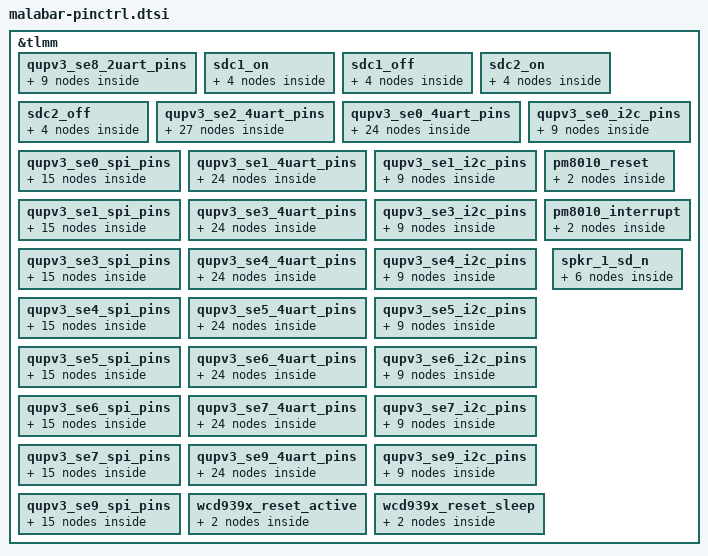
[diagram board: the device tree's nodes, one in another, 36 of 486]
// SPDX-License-Identifier: BSD-3-Clause
/*
 * Copyright (c) Qualcomm Technologies, Inc. and/or its subsidiaries.
 */

&tlmm {
	qupv3_se8_2uart_pins: qupv3_se8_2uart_pins {
		qupv3_se8_2uart_tx_active: qupv3_se8_2uart_tx_active {
			mux {
				pins = "gpio15";
				function = "qup1_se3_l2";
			};

			config {
				pins = "gpio15";
				drive-strength = <2>;
				bias-disable;
			};
		};

		qupv3_se8_2uart_rx_active: qupv3_se8_2uart_rx_active {
			mux {
				pins = "gpio16";
				function = "qup1_se3_l3";
			};

			config {
				pins = "gpio16";
				drive-strength = <2>;
				bias-disable;
			};
		};

		qupv3_se8_2uart_sleep: qupv3_se8_2uart_sleep {
			mux {
				pins = "gpio15", "gpio16";
				function = "gpio";
			};

			config {
				pins = "gpio15", "gpio16";
				drive-strength = <2>;
				bias-pull-down;
			};
		};
	};

	sdc1_on: sdc1_on {
		clk {
			pins = "sdc1_clk";
			bias-disable;
			drive-strength = <16>;
		};

		cmd {
			pins = "sdc1_cmd";
			bias-pull-up;
			drive-strength = <10>;
		};

		data {
			pins = "sdc1_data";
			bias-pull-up;
			drive-strength = <10>;
		};

		rclk {
			pins = "sdc1_rclk";
			bias-pull-down;
		};
	};

	sdc1_off: sdc1_off {
		clk {
			pins = "sdc1_clk";
			bias-disable;
			drive-strength = <2>;
		};

		cmd {
			pins = "sdc1_cmd";
			bias-pull-up;
			drive-strength = <2>;
		};

		data {
			pins = "sdc1_data";
			bias-pull-up;
			drive-strength = <2>;
		};

		rclk {
			pins = "sdc1_rclk";
			bias-pull-down;
		};
	};

	sdc2_on: sdc2_on {
		clk {
			pins = "sdc2_clk";
			bias-disable;
			drive-strength = <16>;
		};

		cmd {
			pins = "sdc2_cmd";
			bias-pull-up;
			drive-strength = <10>;
		};

		data {
			pins = "sdc2_data";
			bias-pull-up;
			drive-strength = <10>;
		};

		sd-cd {
			pins = "gpio79";
			bias-pull-up;
			drive-strength = <2>;
		};
	};

	sdc2_off: sdc2_off {
		clk {
			pins = "sdc2_clk";
			bias-disable;
			drive-strength = <2>;
		};

		cmd {
			pins = "sdc2_cmd";
			bias-pull-up;
			drive-strength = <2>;
		};

		data {
			pins = "sdc2_data";
			bias-pull-up;
			drive-strength = <2>;
		};

		sd-cd {
			pins = "gpio79";
			bias-pull-up;
			drive-strength = <2>;
		};
	};

	qupv3_se2_4uart_pins: qupv3_se2_4uart_pins {
		qupv3_se2_default_cts: qupv3_se2_default_cts {
			mux {
				pins = "gpio17";
				function = "gpio";
			};

			config {
				pins = "gpio17";
				drive-strength = <2>;
				bias-pull-down;
			};
		};

		qupv3_se2_default_rts: qupv3_se2_default_rts {
			mux {
				pins = "gpio18";
				function = "gpio";
			};

			config {
				pins = "gpio18";
				drive-strength = <2>;
				bias-pull-down;
			};
		};

		qupv3_se2_default_tx: qupv3_se2_default_tx {
			mux {
				pins = "gpio19";
				function = "gpio";
			};

			config {
				pins = "gpio19";
				drive-strength = <2>;
				bias-pull-up;
			};
		};

		qupv3_se2_default_rx: qupv3_se2_default_rx {
			mux {
				pins = "gpio20";
				function = "gpio";
			};

			config {
				pins = "gpio20";
				drive-strength = <2>;
				bias-pull-down;
			};
		};

		qupv3_se2_cts: qupv3_se2_cts {
			mux {
				pins = "gpio17";
				function = "qup0_se2_l0";
			};

			config {
				pins = "gpio17";
				drive-strength = <2>;
				bias-disable;
			};
		};

		qupv3_se2_rts: qupv3_se2_rts {
			mux {
				pins = "gpio18";
				function = "qup0_se2_l1";
			};

			config {
				pins = "gpio18";
				drive-strength = <2>;
				bias-pull-down;
			};
		};

		qupv3_se2_tx: qupv3_se2_tx {
			mux {
				pins = "gpio19";
				function = "qup0_se2_l2";
			};

			config {
				pins = "gpio19";
				drive-strength = <2>;
				bias-pull-up;
			};
		};

		qupv3_se2_rx_active: qupv3_se2_rx_active {
			mux {
				pins = "gpio20";
				function = "qup0_se2_l3";
			};

			config {
				pins = "gpio20";
				drive-strength = <2>;
				bias-disable;
			};
		};

		qupv3_se2_rx_wake: qupv3_se2_rx_wake {
			mux {
				pins = "gpio20";
				function = "gpio";
			};

			config {
				pins = "gpio20";
				drive-strength = <2>;
				bias-disable;
			};
		};
	};

	qupv3_se0_4uart_pins: qupv3_se0_4uart_pins {
		qupv3_se0_default_cts: qupv3_se0_default_cts {
			mux {
				pins = "gpio0";
				function = "gpio";
			};

			config {
				pins = "gpio0";
				drive-strength = <2>;
				bias-disable;
			};
		};

		qupv3_se0_default_rts: qupv3_se0_default_rts {
			mux {
				pins = "gpio1";
				function = "gpio";
			};

			config {
				pins = "gpio1";
				drive-strength = <2>;
				bias-pull-down;
			};
		};

		qupv3_se0_default_tx: qupv3_se0_default_tx {
			mux {
				pins = "gpio2";
				function = "gpio";
			};

			config {
				pins = "gpio2";
				drive-strength = <2>;
				bias-pull-up;
			};
		};

		qupv3_se0_default_rx: qupv3_se0_default_rx {
			mux {
				pins = "gpio3";
				function = "gpio";
			};

			config {
				pins = "gpio3";
				drive-strength = <2>;
				bias-pull-down;
			};
		};

		qupv3_se0_cts: qupv3_se0_cts {
			mux {
				pins = "gpio0";
				function = "qup0_se0_l0";
			};

			config {
				pins = "gpio0";
				drive-strength = <2>;
				bias-disable;
			};
		};

		qupv3_se0_rts: qupv3_se0_rts {
			mux {
				pins = "gpio1";
				function = "qup0_se0_l1";
			};

			config {
				pins = "gpio1";
				drive-strength = <2>;
				bias-pull-down;
			};
		};

		qupv3_se0_tx: qupv3_se0_tx {
			mux {
				pins = "gpio2";
				function = "qup0_se0_l2";
			};

			config {
				pins = "gpio2";
				drive-strength = <2>;
				bias-pull-up;
			};
		};

		qupv3_se0_rx_active: qupv3_se0_rx_active {
			mux {
				pins = "gpio3";
				function = "qup0_se0_l3";
			};

			config {
				pins = "gpio3";
				drive-strength = <2>;
				bias-disable;
			};
		};
	};

	qupv3_se0_i2c_pins: qupv3_se0_i2c_pins {
		qupv3_se0_i2c_sda_active: qupv3_se0_i2c_sda_active {
			mux {
				pins = "gpio0";
				function = "qup0_se0_l0";
			};

			config {
				pins = "gpio0";
				drive-strength = <2>;
				bias-pull-up;
			};
		};

		qupv3_se0_i2c_scl_active: qupv3_se0_i2c_scl_active {
			mux {
				pins = "gpio1";
				function = "qup0_se0_l1";
			};

			config {
				pins = "gpio1";
				drive-strength = <2>;
				bias-pull-up;
			};
		};

		qupv3_se0_i2c_sleep: qupv3_se0_i2c_sleep {
			mux {
				pins = "gpio0", "gpio1";
				function = "gpio";
			};

			config {
				pins = "gpio0", "gpio1";
				drive-strength = <2>;
				bias-disable;
			};
		};
	};

	qupv3_se0_spi_pins: qupv3_se0_spi_pins {
		qupv3_se0_spi_miso_active: qupv3_se0_spi_miso_active {
			mux {
				pins = "gpio0";
				function = "qup0_se0_l0";
			};

			config {
				pins = "gpio0";
				drive-strength = <6>;
				bias-disable;
			};
		};

		qupv3_se0_spi_mosi_active: qupv3_se0_spi_mosi_active {
			mux {
				pins = "gpio1";
				function = "qup0_se0_l1";
			};

			config {
				pins = "gpio1";
				drive-strength = <6>;
				bias-disable;
			};
		};

		qupv3_se0_spi_clk_active: qupv3_se0_spi_clk_active {
			mux {
				pins = "gpio2";
				function = "qup0_se0_l2";
			};

			config {
				pins = "gpio2";
				drive-strength = <6>;
				bias-disable;
			};
		};

		qupv3_se0_spi_cs_active: qupv3_se0_spi_cs_active {
			mux {
				pins = "gpio3";
				function = "qup0_se0_l3";
			};

			config {
				pins = "gpio3";
				drive-strength = <6>;
				bias-disable;
			};
		};

		qupv3_se0_spi_sleep: qupv3_se0_spi_sleep {
			mux {
				pins = "gpio0", "gpio1",
					"gpio2", "gpio3";
				function = "gpio";
			};

			config {
				pins = "gpio0", "gpio1",
					"gpio2", "gpio3";
				drive-strength = <2>;
				bias-disable;
			};
		};
	};

	qupv3_se1_4uart_pins: qupv3_se1_4uart_pins {
		qupv3_se1_default_cts: qupv3_se1_default_cts {
			mux {
				pins = "gpio4";
				function = "gpio";
			};

			config {
				pins = "gpio4";
				drive-strength = <2>;
				bias-disable;
			};
		};

		qupv3_se1_default_rts: qupv3_se1_default_rts {
			mux {
				pins = "gpio5";
				function = "gpio";
			};

			config {
				pins = "gpio5";
				drive-strength = <2>;
				bias-pull-down;
			};
		};

		qupv3_se1_default_tx: qupv3_se1_default_tx {
			mux {
				pins = "gpio23";
				function = "gpio";
			};

			config {
				pins = "gpio23";
				drive-strength = <2>;
				bias-pull-up;
			};
		};

		qupv3_se1_default_rx: qupv3_se1_default_rx {
			mux {
				pins = "gpio77";
				function = "gpio";
			};

			config {
				pins = "gpio77";
				drive-strength = <2>;
				bias-pull-down;
			};
		};

		qupv3_se1_cts: qupv3_se1_cts {
			mux {
				pins = "gpio4";
				function = "qup0_se1_l0";
			};

			config {
				pins = "gpio4";
				drive-strength = <2>;
				bias-disable;
			};
		};

		qupv3_se1_rts: qupv3_se1_rts {
			mux {
				pins = "gpio5";
				function = "qup0_se1_l1";
			};

			config {
				pins = "gpio5";
				drive-strength = <2>;
				bias-pull-down;
			};
		};

		qupv3_se1_tx: qupv3_se1_tx {
			mux {
				pins = "gpio23";
				function = "qup0_se1_l2";
			};

			config {
				pins = "gpio23";
				drive-strength = <2>;
				bias-pull-up;
			};
		};

		qupv3_se1_rx_active: qupv3_se1_rx_active {
			mux {
				pins = "gpio77";
				function = "qup0_se1_l3";
			};

			config {
				pins = "gpio77";
				drive-strength = <2>;
				bias-disable;
			};
		};
	};

	qupv3_se1_i2c_pins: qupv3_se1_i2c_pins {
		qupv3_se1_i2c_sda_active: qupv3_se1_i2c_sda_active {
			mux {
				pins = "gpio4";
				function = "qup0_se1_l0";
			};

			config {
				pins = "gpio4";
				drive-strength = <2>;
				bias-pull-up;
			};
		};

		qupv3_se1_i2c_scl_active: qupv3_se1_i2c_scl_active {
			mux {
				pins = "gpio5";
				function = "qup0_se1_l1";
			};

			config {
				pins = "gpio5";
				drive-strength = <2>;
				bias-pull-up;
			};
		};

		qupv3_se1_i2c_sleep: qupv3_se1_i2c_sleep {
			mux {
				pins = "gpio4", "gpio5";
				function = "gpio";
			};

			config {
				pins = "gpio4", "gpio5";
				drive-strength = <2>;
				bias-disable;
			};
		};
	};

	qupv3_se1_spi_pins: qupv3_se1_spi_pins {
		qupv3_se1_spi_miso_active: qupv3_se1_spi_miso_active {
			mux {
				pins = "gpio4";
				function = "qup0_se1_l0";
			};

			config {
				pins = "gpio4";
				drive-strength = <6>;
				bias-disable;
			};
		};

		qupv3_se1_spi_mosi_active: qupv3_se1_spi_mosi_active {
			mux {
				pins = "gpio5";
				function = "qup0_se1_l1";
			};

			config {
				pins = "gpio5";
				drive-strength = <6>;
				bias-disable;
			};
		};

		qupv3_se1_spi_clk_active: qupv3_se1_spi_clk_active {
			mux {
				pins = "gpio23";
				function = "qup0_se1_l2";
			};

			config {
				pins = "gpio23";
				drive-strength = <6>;
				bias-disable;
			};
		};

		qupv3_se1_spi_cs_active: qupv3_se1_spi_cs_active {
			mux {
				pins = "gpio77";
				function = "qup0_se1_l3";
			};

			config {
				pins = "gpio77";
				drive-strength = <6>;
				bias-disable;
			};
		};

		qupv3_se1_spi_sleep: qupv3_se1_spi_sleep {
			mux {
				pins = "gpio4", "gpio5",
					"gpio23", "gpio77";
				function = "gpio";
			};

			config {
				pins = "gpio4", "gpio5",
					"gpio23", "gpio77";
				drive-strength = <2>;
				bias-disable;
			};
		};
	};

	qupv3_se3_4uart_pins: qupv3_se3_4uart_pins {
		qupv3_se3_default_cts: qupv3_se3_default_cts {
			mux {
				pins = "gpio8";
				function = "gpio";
			};

			config {
				pins = "gpio8";
				drive-strength = <2>;
				bias-disable;
			};
		};

		qupv3_se3_default_rts: qupv3_se3_default_rts {
			mux {
				pins = "gpio9";
				function = "gpio";
			};

			config {
				pins = "gpio9";
				drive-strength = <2>;
				bias-pull-down;
			};
		};

		qupv3_se3_default_tx: qupv3_se3_default_tx {
			mux {
				pins = "gpio10";
				function = "gpio";
			};

			config {
				pins = "gpio10";
				drive-strength = <2>;
				bias-pull-up;
			};
		};

		qupv3_se3_default_rx: qupv3_se3_default_rx {
			mux {
				pins = "gpio11";
				function = "gpio";
			};

			config {
				pins = "gpio11";
				drive-strength = <2>;
				bias-pull-down;
			};
		};

		qupv3_se3_cts: qupv3_se3_cts {
			mux {
				pins = "gpio8";
				function = "qup0_se3_l0";
			};

			config {
				pins = "gpio8";
				drive-strength = <2>;
				bias-disable;
			};
		};

		qupv3_se3_rts: qupv3_se3_rts {
			mux {
				pins = "gpio9";
				function = "qup0_se3_l1";
			};

			config {
				pins = "gpio9";
				drive-strength = <2>;
				bias-pull-down;
			};
		};

		qupv3_se3_tx: qupv3_se3_tx {
			mux {
				pins = "gpio10";
				function = "qup0_se3_l2";
			};

			config {
				pins = "gpio10";
				drive-strength = <2>;
				bias-pull-up;
			};
		};

		qupv3_se3_rx_active: qupv3_se3_rx_active {
			mux {
				pins = "gpio11";
				function = "qup0_se3_l3";
			};

			config {
				pins = "gpio11";
				drive-strength = <2>;
				bias-disable;
			};
		};
	};

	qupv3_se3_i2c_pins: qupv3_se3_i2c_pins {
		qupv3_se3_i2c_sda_active: qupv3_se3_i2c_sda_active {
			mux {
				pins = "gpio8";
				function = "qup0_se3_l0";
			};

			config {
				pins = "gpio8";
				drive-strength = <2>;
				bias-pull-up;
			};
		};

		qupv3_se3_i2c_scl_active: qupv3_se3_i2c_scl_active {
			mux {
				pins = "gpio9";
				function = "qup0_se3_l1";
			};

			config {
				pins = "gpio9";
				drive-strength = <2>;
				bias-pull-up;
			};
		};

		qupv3_se3_i2c_sleep: qupv3_se3_i2c_sleep {
			mux {
				pins = "gpio8", "gpio9";
				function = "gpio";
			};

			config {
				pins = "gpio8", "gpio9";
				drive-strength = <2>;
				bias-disable;
			};
		};
	};

	qupv3_se3_spi_pins: qupv3_se3_spi_pins {
		qupv3_se3_spi_miso_active: qupv3_se3_spi_miso_active {
			mux {
				pins = "gpio8";
				function = "qup0_se3_l0";
			};

			config {
				pins = "gpio8";
				drive-strength = <6>;
				bias-disable;
			};
		};

		qupv3_se3_spi_mosi_active: qupv3_se3_spi_mosi_active {
			mux {
				pins = "gpio9";
				function = "qup0_se3_l1";
			};

			config {
				pins = "gpio9";
				drive-strength = <6>;
				bias-disable;
			};
		};

		qupv3_se3_spi_clk_active: qupv3_se3_spi_clk_active {
			mux {
				pins = "gpio10";
				function = "qup0_se3_l2";
			};

			config {
				pins = "gpio10";
				drive-strength = <6>;
				bias-disable;
			};
		};

		qupv3_se3_spi_cs_active: qupv3_se3_spi_cs_active {
			mux {
				pins = "gpio11";
				function = "qup0_se3_l3";
			};

			config {
				pins = "gpio11";
				drive-strength = <6>;
				bias-disable;
			};
		};

		qupv3_se3_spi_sleep: qupv3_se3_spi_sleep {
			mux {
				pins = "gpio8", "gpio9",
					"gpio10", "gpio11";
				function = "gpio";
			};

			config {
				pins = "gpio8", "gpio9",
					"gpio10", "gpio11";
				drive-strength = <2>;
				bias-disable;
			};
		};
	};

	qupv3_se4_4uart_pins: qupv3_se4_4uart_pins {
		qupv3_se4_default_cts: qupv3_se4_default_cts {
			mux {
				pins = "gpio6";
				function = "gpio";
			};

			config {
				pins = "gpio6";
				drive-strength = <2>;
				bias-disable;
			};
		};

		qupv3_se4_default_rts: qupv3_se4_default_rts {
			mux {
				pins = "gpio7";
				function = "gpio";
			};

			config {
				pins = "gpio7";
				drive-strength = <2>;
				bias-pull-down;
			};
		};

		qupv3_se4_default_tx: qupv3_se4_default_tx {
			mux {
				pins = "gpio12";
				function = "gpio";
			};

			config {
				pins = "gpio12";
				drive-strength = <2>;
				bias-pull-up;
			};
		};

		qupv3_se4_default_rx: qupv3_se4_default_rx {
			mux {
				pins = "gpio13";
				function = "gpio";
			};

			config {
				pins = "gpio13";
				drive-strength = <2>;
				bias-pull-down;
			};
		};

		qupv3_se4_cts: qupv3_se4_cts {
			mux {
				pins = "gpio6";
				function = "qup0_se4_l0";
			};

			config {
				pins = "gpio6";
				drive-strength = <2>;
				bias-disable;
			};
		};

		qupv3_se4_rts: qupv3_se4_rts {
			mux {
				pins = "gpio7";
				function = "qup0_se4_l1";
			};

			config {
				pins = "gpio7";
				drive-strength = <2>;
				bias-pull-down;
			};
		};

		qupv3_se4_tx: qupv3_se4_tx {
			mux {
				pins = "gpio12";
				function = "qup0_se4_l2";
			};

			config {
				pins = "gpio12";
				drive-strength = <2>;
				bias-pull-up;
			};
		};

		qupv3_se4_rx_active: qupv3_se4_rx_active {
			mux {
				pins = "gpio13";
				function = "qup0_se4_l3";
			};

			config {
				pins = "gpio13";
				drive-strength = <2>;
				bias-disable;
			};
		};
	};

	qupv3_se4_i2c_pins: qupv3_se4_i2c_pins {
		qupv3_se4_i2c_sda_active: qupv3_se4_i2c_sda_active {
			mux {
				pins = "gpio6";
				function = "qup0_se4_l0";
			};

			config {
				pins = "gpio6";
				drive-strength = <2>;
				bias-pull-up;
			};
		};

		qupv3_se4_i2c_scl_active: qupv3_se4_i2c_scl_active {
			mux {
				pins = "gpio7";
				function = "qup0_se4_l1";
			};

			config {
				pins = "gpio7";
				drive-strength = <2>;
				bias-pull-up;
			};
		};

		qupv3_se4_i2c_sleep: qupv3_se4_i2c_sleep {
			mux {
				pins = "gpio6", "gpio7";
				function = "gpio";
			};

			config {
				pins = "gpio6", "gpio7";
				drive-strength = <2>;
				bias-disable;
			};
		};
	};

	qupv3_se4_spi_pins: qupv3_se4_spi_pins {
		qupv3_se4_spi_miso_active: qupv3_se4_spi_miso_active {
			mux {
				pins = "gpio6";
				function = "qup0_se4_l0";
			};

			config {
				pins = "gpio6";
				drive-strength = <6>;
				bias-disable;
			};
		};

		qupv3_se4_spi_mosi_active: qupv3_se4_spi_mosi_active {
			mux {
				pins = "gpio7";
				function = "qup0_se4_l1";
			};

			config {
				pins = "gpio7";
				drive-strength = <6>;
				bias-disable;
			};
		};

		qupv3_se4_spi_clk_active: qupv3_se4_spi_clk_active {
			mux {
				pins = "gpio12";
				function = "qup0_se4_l2";
			};

			config {
				pins = "gpio12";
				drive-strength = <6>;
				bias-disable;
			};
		};

		qupv3_se4_spi_cs_active: qupv3_se4_spi_cs_active {
			mux {
				pins = "gpio13";
				function = "qup0_se4_l3";
			};

			config {
				pins = "gpio13";
				drive-strength = <6>;
				bias-disable;
			};
		};

		qupv3_se4_spi_sleep: qupv3_se4_spi_sleep {
			mux {
				pins = "gpio6", "gpio7",
					"gpio12", "gpio13";
				function = "gpio";
			};

			config {
				pins = "gpio6", "gpio7",
					"gpio12", "gpio13";
				drive-strength = <2>;
				bias-disable;
			};
		};
	};

	qupv3_se5_4uart_pins: qupv3_se5_4uart_pins {
		qupv3_se5_default_cts: qupv3_se5_default_cts {
			mux {
				pins = "gpio36";
				function = "gpio";
			};

			config {
				pins = "gpio36";
				drive-strength = <2>;
				bias-disable;
			};
		};

		qupv3_se5_default_rts: qupv3_se5_default_rts {
			mux {
				pins = "gpio37";
				function = "gpio";
			};

			config {
				pins = "gpio37";
				drive-strength = <2>;
				bias-pull-down;
			};
		};

		qupv3_se5_default_tx: qupv3_se5_default_tx {
			mux {
				pins = "gpio38";
				function = "gpio";
			};

			config {
				pins = "gpio38";
				drive-strength = <2>;
				bias-pull-up;
			};
		};

		qupv3_se5_default_rx: qupv3_se5_default_rx {
			mux {
				pins = "gpio39";
				function = "gpio";
			};

			config {
				pins = "gpio39";
				drive-strength = <2>;
				bias-pull-down;
			};
		};

		qupv3_se5_cts: qupv3_se5_cts {
			mux {
				pins = "gpio36";
				function = "qup1_se0_l0";
			};

			config {
				pins = "gpio36";
				drive-strength = <2>;
				bias-disable;
			};
		};

		qupv3_se5_rts: qupv3_se5_rts {
			mux {
				pins = "gpio37";
				function = "qup1_se0_l1";
			};

			config {
				pins = "gpio37";
				drive-strength = <2>;
				bias-pull-down;
			};
		};

		qupv3_se5_tx: qupv3_se5_tx {
			mux {
				pins = "gpio38";
				function = "qup1_se0_l2";
			};

			config {
				pins = "gpio38";
				drive-strength = <2>;
				bias-pull-up;
			};
		};

		qupv3_se5_rx_active: qupv3_se5_rx_active {
			mux {
				pins = "gpio39";
				function = "qup1_se0_l3";
			};

			config {
				pins = "gpio39";
				drive-strength = <2>;
				bias-disable;
			};
		};
	};

	qupv3_se5_i2c_pins: qupv3_se5_i2c_pins {
		qupv3_se5_i2c_sda_active: qupv3_se5_i2c_sda_active {
			mux {
				pins = "gpio36";
				function = "qup1_se0_l0";
			};

			config {
				pins = "gpio36";
				drive-strength = <2>;
				bias-pull-up;
			};
		};

		qupv3_se5_i2c_scl_active: qupv3_se5_i2c_scl_active {
			mux {
				pins = "gpio37";
				function = "qup1_se0_l1";
			};

			config {
				pins = "gpio37";
				drive-strength = <2>;
				bias-pull-up;
			};
		};

		qupv3_se5_i2c_sleep: qupv3_se5_i2c_sleep {
			mux {
				pins = "gpio36", "gpio37";
				function = "gpio";
			};

			config {
				pins = "gpio36", "gpio37";
				drive-strength = <2>;
				bias-disable;
			};
		};
	};

	qupv3_se5_spi_pins: qupv3_se5_spi_pins {
		qupv3_se5_spi_miso_active: qupv3_se5_spi_miso_active {
			mux {
				pins = "gpio36";
				function = "qup1_se0_l0";
			};

			config {
				pins = "gpio36";
				drive-strength = <6>;
				bias-disable;
			};
		};

		qupv3_se5_spi_mosi_active: qupv3_se5_spi_mosi_active {
			mux {
				pins = "gpio37";
				function = "qup1_se0_l1";
			};

			config {
				pins = "gpio37";
				drive-strength = <6>;
				bias-disable;
			};
		};

		qupv3_se5_spi_clk_active: qupv3_se5_spi_clk_active {
			mux {
				pins = "gpio38";
				function = "qup1_se0_l2";
			};

			config {
				pins = "gpio38";
				drive-strength = <6>;
				bias-disable;
			};
		};

		qupv3_se5_spi_cs_active: qupv3_se5_spi_cs_active {
			mux {
				pins = "gpio39";
				function = "qup1_se0_l3";
			};

			config {
				pins = "gpio39";
				drive-strength = <6>;
				bias-disable;
			};
		};

		qupv3_se5_spi_sleep: qupv3_se5_spi_sleep {
			mux {
				pins = "gpio36", "gpio37",
					"gpio38", "gpio39";
				function = "gpio";
			};

			config {
				pins = "gpio36", "gpio37",
					"gpio38", "gpio39";
				drive-strength = <2>;
				bias-disable;
			};
		};
	};

	qupv3_se6_4uart_pins: qupv3_se6_4uart_pins {
		qupv3_se6_default_cts: qupv3_se6_default_cts {
			mux {
				pins = "gpio78";
				function = "gpio";
			};

			config {
				pins = "gpio78";
				drive-strength = <2>;
				bias-disable;
			};
		};

		qupv3_se6_default_rts: qupv3_se6_default_rts {
			mux {
				pins = "gpio79";
				function = "gpio";
			};

			config {
				pins = "gpio79";
				drive-strength = <2>;
				bias-pull-down;
			};
		};

		qupv3_se6_default_tx: qupv3_se6_default_tx {
			mux {
				pins = "gpio69";
				function = "gpio";
			};

			config {
				pins = "gpio69";
				drive-strength = <2>;
				bias-pull-up;
			};
		};

		qupv3_se6_default_rx: qupv3_se6_default_rx {
			mux {
				pins = "gpio70";
				function = "gpio";
			};

			config {
				pins = "gpio70";
				drive-strength = <2>;
				bias-pull-down;
			};
		};

		qupv3_se6_cts: qupv3_se6_cts {
			mux {
				pins = "gpio78";
				function = "qup1_se1_l0";
			};

			config {
				pins = "gpio78";
				drive-strength = <2>;
				bias-disable;
			};
		};

		qupv3_se6_rts: qupv3_se6_rts {
			mux {
				pins = "gpio79";
				function = "qup1_se1_l1";
			};

			config {
				pins = "gpio79";
				drive-strength = <2>;
				bias-pull-down;
			};
		};

		qupv3_se6_tx: qupv3_se6_tx {
			mux {
				pins = "gpio69";
				function = "qup1_se1_l2";
			};

			config {
				pins = "gpio69";
				drive-strength = <2>;
				bias-pull-up;
			};
		};

		qupv3_se6_rx_active: qupv3_se6_rx_active {
			mux {
				pins = "gpio70";
				function = "qup1_se1_l3";
			};

			config {
				pins = "gpio70";
				drive-strength = <2>;
				bias-disable;
			};
		};
	};

	qupv3_se6_i2c_pins: qupv3_se6_i2c_pins {
		qupv3_se6_i2c_sda_active: qupv3_se6_i2c_sda_active {
			mux {
				pins = "gpio78";
				function = "qup1_se1_l0";
			};

			config {
				pins = "gpio78";
				drive-strength = <2>;
				bias-pull-up;
			};
		};

		qupv3_se6_i2c_scl_active: qupv3_se6_i2c_scl_active {
			mux {
				pins = "gpio79";
				function = "qup1_se1_l1";
			};

			config {
				pins = "gpio79";
				drive-strength = <2>;
				bias-pull-up;
			};
		};

		qupv3_se6_i2c_sleep: qupv3_se6_i2c_sleep {
			mux {
				pins = "gpio78", "gpio79";
				function = "gpio";
			};

			config {
				pins = "gpio78", "gpio79";
				drive-strength = <2>;
				bias-disable;
			};
		};
	};

	qupv3_se6_spi_pins: qupv3_se6_spi_pins {
		qupv3_se6_spi_miso_active: qupv3_se6_spi_miso_active {
			mux {
				pins = "gpio78";
				function = "qup1_se1_l0";
			};

			config {
				pins = "gpio78";
				drive-strength = <6>;
				bias-disable;
			};
		};

		qupv3_se6_spi_mosi_active: qupv3_se6_spi_mosi_active {
			mux {
				pins = "gpio79";
				function = "qup1_se1_l1";
			};

			config {
				pins = "gpio79";
				drive-strength = <6>;
				bias-disable;
			};
		};

		qupv3_se6_spi_clk_active: qupv3_se6_spi_clk_active {
			mux {
				pins = "gpio69";
				function = "qup1_se1_l2";
			};

			config {
				pins = "gpio69";
				drive-strength = <6>;
				bias-disable;
			};
		};

		qupv3_se6_spi_cs_active: qupv3_se6_spi_cs_active {
			mux {
				pins = "gpio70";
				function = "qup1_se1_l3";
			};

			config {
				pins = "gpio70";
				drive-strength = <6>;
				bias-disable;
			};
		};

		qupv3_se6_spi_sleep: qupv3_se6_spi_sleep {
			mux {
				pins = "gpio78", "gpio79",
					"gpio69", "gpio70";
				function = "gpio";
			};

			config {
				pins = "gpio78", "gpio79",
					"gpio69", "gpio70";
				drive-strength = <2>;
				bias-disable;
			};
		};
	};

	qupv3_se7_4uart_pins: qupv3_se7_4uart_pins {
		qupv3_se7_default_cts: qupv3_se7_default_cts {
			mux {
				pins = "gpio40";
				function = "gpio";
			};

			config {
				pins = "gpio40";
				drive-strength = <2>;
				bias-disable;
			};
		};

		qupv3_se7_default_rts: qupv3_se7_default_rts {
			mux {
				pins = "gpio41";
				function = "gpio";
			};

			config {
				pins = "gpio41";
				drive-strength = <2>;
				bias-pull-down;
			};
		};

		qupv3_se7_default_tx: qupv3_se7_default_tx {
			mux {
				pins = "gpio42";
				function = "gpio";
			};

			config {
				pins = "gpio42";
				drive-strength = <2>;
				bias-pull-up;
			};
		};

		qupv3_se7_default_rx: qupv3_se7_default_rx {
			mux {
				pins = "gpio43";
				function = "gpio";
			};

			config {
				pins = "gpio43";
				drive-strength = <2>;
				bias-pull-down;
			};
		};

		qupv3_se7_cts: qupv3_se7_cts {
			mux {
				pins = "gpio40";
				function = "qup1_se2_l0";
			};

			config {
				pins = "gpio40";
				drive-strength = <2>;
				bias-disable;
			};
		};

		qupv3_se7_rts: qupv3_se7_rts {
			mux {
				pins = "gpio41";
				function = "qup1_se2_l1";
			};

			config {
				pins = "gpio41";
				drive-strength = <2>;
				bias-pull-down;
			};
		};

		qupv3_se7_tx: qupv3_se7_tx {
			mux {
				pins = "gpio42";
				function = "qup1_se2_l2";
			};

			config {
				pins = "gpio42";
				drive-strength = <2>;
				bias-pull-up;
			};
		};

		qupv3_se7_rx_active: qupv3_se7_rx_active {
			mux {
				pins = "gpio43";
				function = "qup1_se2_l3";
			};

			config {
				pins = "gpio43";
				drive-strength = <2>;
				bias-disable;
			};
		};
	};

	qupv3_se7_i2c_pins: qupv3_se7_i2c_pins {
		qupv3_se7_i2c_sda_active: qupv3_se7_i2c_sda_active {
			mux {
				pins = "gpio40";
				function = "qup1_se2_l0";
			};

			config {
				pins = "gpio40";
				drive-strength = <2>;
				bias-pull-up;
			};
		};

		qupv3_se7_i2c_scl_active: qupv3_se7_i2c_scl_active {
			mux {
				pins = "gpio41";
				function = "qup1_se2_l1";
			};

			config {
				pins = "gpio41";
				drive-strength = <2>;
				bias-pull-up;
			};
		};

		qupv3_se7_i2c_sleep: qupv3_se7_i2c_sleep {
			mux {
				pins = "gpio40", "gpio41";
				function = "gpio";
			};

			config {
				pins = "gpio40", "gpio41";
				drive-strength = <2>;
				bias-disable;
			};
		};
	};

	qupv3_se7_spi_pins: qupv3_se7_spi_pins {
		qupv3_se7_spi_miso_active: qupv3_se7_spi_miso_active {
			mux {
				pins = "gpio40";
				function = "qup1_se2_l0";
			};

			config {
				pins = "gpio40";
				drive-strength = <6>;
				bias-disable;
			};
		};

		qupv3_se7_spi_mosi_active: qupv3_se7_spi_mosi_active {
			mux {
				pins = "gpio41";
				function = "qup1_se2_l1";
			};

			config {
				pins = "gpio41";
				drive-strength = <6>;
				bias-disable;
			};
		};

		qupv3_se7_spi_clk_active: qupv3_se7_spi_clk_active {
			mux {
				pins = "gpio42";
				function = "qup1_se2_l2";
			};

			config {
				pins = "gpio42";
				drive-strength = <6>;
				bias-disable;
			};
		};

		qupv3_se7_spi_cs_active: qupv3_se7_spi_cs_active {
			mux {
				pins = "gpio43";
				function = "qup1_se2_l3";
			};

			config {
				pins = "gpio43";
				drive-strength = <6>;
				bias-disable;
			};
		};

		qupv3_se7_spi_sleep: qupv3_se7_spi_sleep {
			mux {
				pins = "gpio40", "gpio41",
					"gpio42", "gpio43";
				function = "gpio";
			};

			config {
				pins = "gpio40", "gpio41",
					"gpio42", "gpio43";
				drive-strength = <2>;
				bias-disable;
			};
		};
	};

	qupv3_se9_4uart_pins: qupv3_se9_4uart_pins {
		qupv3_se9_default_cts: qupv3_se9_default_cts {
			mux {
				pins = "gpio71";
				function = "gpio";
			};

			config {
				pins = "gpio71";
				drive-strength = <2>;
				bias-disable;
			};
		};

		qupv3_se9_default_rts: qupv3_se9_default_rts {
			mux {
				pins = "gpio72";
				function = "gpio";
			};

			config {
				pins = "gpio72";
				drive-strength = <2>;
				bias-pull-down;
			};
		};

		qupv3_se9_default_tx: qupv3_se9_default_tx {
			mux {
				pins = "gpio73";
				function = "gpio";
			};

			config {
				pins = "gpio73";
				drive-strength = <2>;
				bias-pull-up;
			};
		};

		qupv3_se9_default_rx: qupv3_se9_default_rx {
			mux {
				pins = "gpio74";
				function = "gpio";
			};

			config {
				pins = "gpio74";
				drive-strength = <2>;
				bias-pull-down;
			};
		};

		qupv3_se9_cts: qupv3_se9_cts {
			mux {
				pins = "gpio71";
				function = "qup1_se4_l0";
			};

			config {
				pins = "gpio71";
				drive-strength = <2>;
				bias-disable;
			};
		};

		qupv3_se9_rts: qupv3_se9_rts {
			mux {
				pins = "gpio72";
				function = "qup1_se4_l1";
			};

			config {
				pins = "gpio72";
				drive-strength = <2>;
				bias-pull-down;
			};
		};

		qupv3_se9_tx: qupv3_se9_tx {
			mux {
				pins = "gpio73";
				function = "qup1_se4_l2";
			};

			config {
				pins = "gpio73";
				drive-strength = <2>;
				bias-pull-up;
			};
		};

		qupv3_se9_rx_active: qupv3_se9_rx_active {
			mux {
				pins = "gpio74";
				function = "qup1_se4_l3";
			};

			config {
				pins = "gpio74";
				drive-strength = <2>;
				bias-disable;
			};
		};
	};

	qupv3_se9_i2c_pins: qupv3_se9_i2c_pins {
		qupv3_se9_i2c_sda_active: qupv3_se9_i2c_sda_active {
			mux {
				pins = "gpio71";
				function = "qup1_se4_l0";
			};

			config {
				pins = "gpio71";
				drive-strength = <2>;
				bias-pull-up;
			};
		};

		qupv3_se9_i2c_scl_active: qupv3_se9_i2c_scl_active {
			mux {
				pins = "gpio72";
				function = "qup1_se4_l1";
			};

			config {
				pins = "gpio72";
				drive-strength = <2>;
				bias-pull-up;
			};
		};

		qupv3_se9_i2c_sleep: qupv3_se9_i2c_sleep {
			mux {
				pins = "gpio71", "gpio72";
				function = "gpio";
			};

			config {
				pins = "gpio71", "gpio72";
				drive-strength = <2>;
				bias-disable;
			};
		};
	};

	qupv3_se9_spi_pins: qupv3_se9_spi_pins {
		qupv3_se9_spi_miso_active: qupv3_se9_spi_miso_active {
			mux {
				pins = "gpio71";
				function = "qup1_se4_l0";
			};

			config {
				pins = "gpio71";
				drive-strength = <6>;
				bias-disable;
			};
		};

		qupv3_se9_spi_mosi_active: qupv3_se9_spi_mosi_active {
			mux {
				pins = "gpio72";
				function = "qup1_se4_l1";
			};

			config {
				pins = "gpio72";
				drive-strength = <6>;
				bias-disable;
			};
		};

		qupv3_se9_spi_clk_active: qupv3_se9_spi_clk_active {
			mux {
				pins = "gpio73";
				function = "qup1_se4_l2";
			};

			config {
				pins = "gpio73";
				drive-strength = <6>;
				bias-disable;
			};
		};

		qupv3_se9_spi_cs_active: qupv3_se9_spi_cs_active {
			mux {
				pins = "gpio74";
				function = "qup1_se4_l3";
			};

			config {
				pins = "gpio74";
				drive-strength = <6>;
				bias-disable;
			};
		};

		qupv3_se9_spi_sleep: qupv3_se9_spi_sleep {
			mux {
				pins = "gpio71", "gpio72",
					"gpio73", "gpio74";
				function = "gpio";
			};

			config {
				pins = "gpio71", "gpio72",
					"gpio73", "gpio74";
				drive-strength = <2>;
				bias-disable;
			};
		};
	};

	pm8010_reset: pm8010_reset {
		mux {
			pins = "gpio112";
			function = "gpio";
		};

		config {
			pins = "gpio112";
			bias-pull-up;
			output-high;
			drive-strength = <2>;
		};
	};

	pm8010_interrupt: pm8010_interrupt {
		mux {
			pins = "gpio113";
			function = "gpio";
		};

		config {
			pins = "gpio113";
			bias-disable;
			input-enable;
		};
	};

	/* WCD reset pin */
	wcd939x_reset_active: wcd939x_reset_active {
		mux {
			 pins = "gpio43";
			 function = "gpio";
		};

		config {
		pins = "gpio43";
			drive-strength = <16>;
			output-high;
		};
	};

	wcd939x_reset_sleep: wcd939x_reset_sleep {
		mux {
			pins = "gpio43";
			function = "gpio";
		};

		config {
			pins = "gpio43";
			drive-strength = <16>;
			bias-disable;
			output-low;
		};
	};

	spkr_1_sd_n {
		spkr_1_sd_n_sleep: spkr_1_sd_n_sleep {
			mux {
				pins = "gpio64";
				function = "gpio";
			};

			config {
				pins = "gpio64";
				drive-strength = <2>;   /* 2 mA */
				bias-pull-down;
				input-enable;
			};
		};

		spkr_1_sd_n_active: spkr_1_sd_n_active {
			mux {
				pins = "gpio64";
				function = "gpio";
			};

			config {
				pins = "gpio64";
				drive-strength = <16>;   /* 16 mA */
				bias-disable;
				output-high;
			};
		};
	};

};
